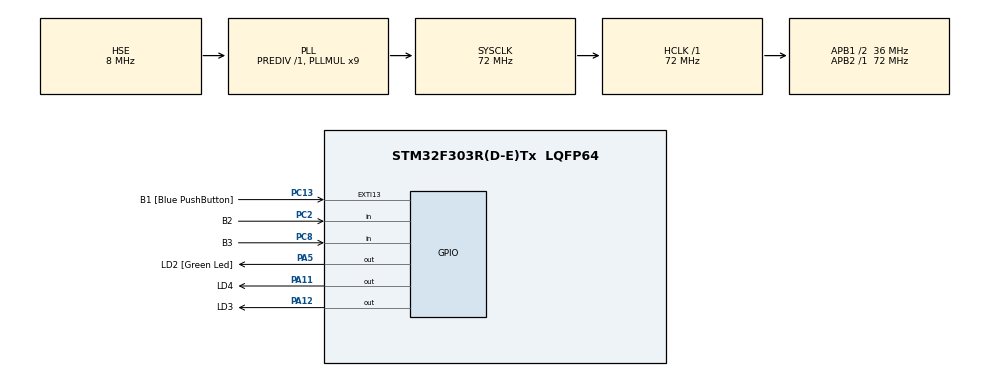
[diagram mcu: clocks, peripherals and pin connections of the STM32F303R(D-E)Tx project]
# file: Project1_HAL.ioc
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Mcu.Family=STM32F3
RCC.PLLSourceVirtual=RCC_PLLSOURCE_HSE
RCC.CortexFreq_Value=72000000
PC13.Signal=GPXTI13
PA14.GPIO_Label=TCK
RCC.SYSCLKSourceVirtual=RCC_SYSCLKSOURCE_PLLCLK
PC8.Signal=GPIO_Input
PC2.Signal=GPIO_Input
PA11.GPIO_Label=LD4
PC13.GPIO_Label=B1 [Blue PushButton]
RCC.APB1CLKDivider=RCC_HCLK_DIV2
PA12.GPIO_Label=LD3
ProjectManager.StackSize=0x400
PC8.GPIO_Label=B3
PA13.Signal=SYS_JTMS-SWDIO
PA12.GPIO_ModeDefaultOutputPP=GPIO_MODE_OUTPUT_OD
PA12.Signal=GPIO_Output
ProjectManager.TargetToolchain=STM32CubeIDE
RCC.HCLKFreq_Value=72000000
RCC.APB2TimFreq_Value=72000000
RCC.USBFreq_Value=72000000
RCC.LSE_VALUE=32768
RCC.AHBFreq_Value=72000000
PF0-OSC_IN.Mode=HSE-External-Oscillator
PA5.Signal=GPIO_Output
PA12.PinState=GPIO_PIN_SET
RCC.HSE_VALUE=8000000
board=NUCLEO-F303RE
RCC.RCC_PLLsource_Clock_Source_FROM_HSE=RCC_HSE_PREDIV_DIV2
RCC.PLLMUL=RCC_PLL_MUL9
PA11.GPIO_ModeDefaultOutputPP=GPIO_MODE_OUTPUT_PP
RCC.APB2Freq_Value=72000000
PA14.Mode=Serial_Wire
PA5.GPIO_PuPd=GPIO_NOPULL
PC2.GPIO_PuPd=GPIO_PULLUP
PA13.Mode=Serial_Wire
Mcu.Name=STM32F303R(D-E)Tx
PA13.GPIO_Label=TMS
PC8.GPIO_PuPd=GPIO_PULLDOWN
RCC.SYSCLKFreq_VALUE=72000000
Mcu.Package=LQFP64
PA5.GPIO_Label=LD2 [Green Led]
PC13.GPIO_ModeDefaultEXTI=GPIO_MODE_IT_FALLING
RCC.EnbaleCSS=true
PA11.Signal=GPIO_Output
PA14.Signal=SYS_JTCK-SWCLK
ProjectManager.HeapSize=0x200
RCC.HSI_VALUE=8000000
RCC.PLLP=RCC_PLLP_DIV4
PA5.GPIO_Speed=GPIO_SPEED_FREQ_LOW
RCC.PLLQ=7
NVIC.PriorityGroup=NVIC_PRIORITYGROUP_0
RCC.PLLM=8
RCC.PLLN=336
RCC.APB1TimFreq_Value=72000000
PF0-OSC_IN.Signal=RCC_OSC_IN
PF1-OSC_OUT.Mode=HSE-External-Oscillator
RCC.APB1Freq_Value=36000000
PA5.GPIO_Mode=GPIO_MODE_OUTPUT_PP
PC2.GPIO_Label=B2
PF1-OSC_OUT.Signal=RCC_OSC_OUT

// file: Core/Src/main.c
/* USER CODE BEGIN Header */
/**
  ******************************************************************************
  * @project-name	: Project 1 (with HAL Library)
  * @file           : main.c
  * @brief          : Main program body
  ******************************************************************************
  * @attention
  *
  * <h2><center>&copy; Copyright (c) 2021 STMicroelectronics.
  * All rights reserved.</center></h2>
  *
  * This software component is licensed by ST under BSD 3-Clause license,
  * the "License"; You may not use this file except in compliance with the
  * License. You may obtain a copy of the License at:
  *                        opensource.org/licenses/BSD-3-Clause
  *
  ******************************************************************************
  */
/* USER CODE END Header */
#include "main.h"

void SystemClock_Config(void);
static void MX_GPIO_Init(void);

int main(void)
{

  /* MCU Configuration--------------------------------------------------------*/

  /* Reset of all peripherals, Initializes the Flash interface and the Systick. */
  HAL_Init();

  /* Configure the system clock */
  SystemClock_Config();

  /* Initialize all configured peripherals */
  MX_GPIO_Init();

  /* Infinite loop */
  /* USER CODE BEGIN WHILE */
  while (1)
  {
	  //Check if the pull-up button is pressed.
	  if(!HAL_GPIO_ReadPin(B2_GPIO_Port, B2_Pin))
	  {

		  //50ms bounce time
		  HAL_Delay(50);

		  //Wait while the pull-up button is pressed.
		  while(!HAL_GPIO_ReadPin(B2_GPIO_Port, B2_Pin));

		  //50ms bounce time
		  HAL_Delay(50);

		  //Change the state of open-drain led
		  HAL_GPIO_TogglePin(LD3_GPIO_Port, LD3_Pin);

	  }

	  //Or check if the pull-down button is pressed.
	  else if (HAL_GPIO_ReadPin(B3_GPIO_Port, B3_Pin))
	  {

		  //50ms bounce time
		  HAL_Delay(50);

		  //Wait while the pull-down button is pressed.
		  while(HAL_GPIO_ReadPin(B3_GPIO_Port, B3_Pin));

		  //50ms bounce time
		  HAL_Delay(50);

		  //Change the state of push-pull led
		  HAL_GPIO_TogglePin(LD4_GPIO_Port, LD4_Pin);
	  }

	  else
	  {
		  continue;
	  }
    /* USER CODE END WHILE */
  }
}

void SystemClock_Config(void)
{
  RCC_OscInitTypeDef RCC_OscInitStruct = {0};
  RCC_ClkInitTypeDef RCC_ClkInitStruct = {0};

  /** Initializes the RCC Oscillators according to the specified parameters
  * in the RCC_OscInitTypeDef structure.
  */
  RCC_OscInitStruct.OscillatorType = RCC_OSCILLATORTYPE_HSE;
  RCC_OscInitStruct.HSEState = RCC_HSE_ON;
  RCC_OscInitStruct.HSIState = RCC_HSI_ON;
  RCC_OscInitStruct.PLL.PLLState = RCC_PLL_ON;
  RCC_OscInitStruct.PLL.PLLSource = RCC_PLLSOURCE_HSE;
  RCC_OscInitStruct.PLL.PLLMUL = RCC_PLL_MUL9;
  RCC_OscInitStruct.PLL.PREDIV = RCC_PREDIV_DIV1;
  if (HAL_RCC_OscConfig(&RCC_OscInitStruct) != HAL_OK)
  {
    Error_Handler();
  }
  /** Initializes the CPU, AHB and APB buses clocks
  */
  RCC_ClkInitStruct.ClockType = RCC_CLOCKTYPE_HCLK|RCC_CLOCKTYPE_SYSCLK
                              |RCC_CLOCKTYPE_PCLK1|RCC_CLOCKTYPE_PCLK2;
  RCC_ClkInitStruct.SYSCLKSource = RCC_SYSCLKSOURCE_PLLCLK;
  RCC_ClkInitStruct.AHBCLKDivider = RCC_SYSCLK_DIV1;
  RCC_ClkInitStruct.APB1CLKDivider = RCC_HCLK_DIV2;
  RCC_ClkInitStruct.APB2CLKDivider = RCC_HCLK_DIV1;

  if (HAL_RCC_ClockConfig(&RCC_ClkInitStruct, FLASH_LATENCY_2) != HAL_OK)
  {
    Error_Handler();
  }
  /** Enables the Clock Security System
  */
  HAL_RCC_EnableCSS();
}

static void MX_GPIO_Init(void)
{
  GPIO_InitTypeDef GPIO_InitStruct = {0};

  /* GPIO Ports Clock Enable */
  __HAL_RCC_GPIOC_CLK_ENABLE();
  __HAL_RCC_GPIOF_CLK_ENABLE();
  __HAL_RCC_GPIOA_CLK_ENABLE();

  /*Configure GPIO pin Output Level */
  HAL_GPIO_WritePin(GPIOA, LD2_Pin|LD4_Pin, GPIO_PIN_RESET);

  /*Configure GPIO pin Output Level */
  HAL_GPIO_WritePin(LD3_GPIO_Port, LD3_Pin, GPIO_PIN_SET);

  /*Configure GPIO pin : B1_Pin */
  GPIO_InitStruct.Pin = B1_Pin;
  GPIO_InitStruct.Mode = GPIO_MODE_IT_FALLING;
  GPIO_InitStruct.Pull = GPIO_NOPULL;
  HAL_GPIO_Init(B1_GPIO_Port, &GPIO_InitStruct);

  /*Configure GPIO pin : B2_Pin */
  GPIO_InitStruct.Pin = B2_Pin;
  GPIO_InitStruct.Mode = GPIO_MODE_INPUT;
  GPIO_InitStruct.Pull = GPIO_PULLUP;
  HAL_GPIO_Init(B2_GPIO_Port, &GPIO_InitStruct);

  /*Configure GPIO pins : LD2_Pin LD4_Pin */
  GPIO_InitStruct.Pin = LD2_Pin|LD4_Pin;
  GPIO_InitStruct.Mode = GPIO_MODE_OUTPUT_PP;
  GPIO_InitStruct.Pull = GPIO_NOPULL;
  GPIO_InitStruct.Speed = GPIO_SPEED_FREQ_LOW;
  HAL_GPIO_Init(GPIOA, &GPIO_InitStruct);

  /*Configure GPIO pin : B3_Pin */
  GPIO_InitStruct.Pin = B3_Pin;
  GPIO_InitStruct.Mode = GPIO_MODE_INPUT;
  GPIO_InitStruct.Pull = GPIO_PULLDOWN;
  HAL_GPIO_Init(B3_GPIO_Port, &GPIO_InitStruct);

  /*Configure GPIO pin : LD3_Pin */
  GPIO_InitStruct.Pin = LD3_Pin;
  GPIO_InitStruct.Mode = GPIO_MODE_OUTPUT_OD;
  GPIO_InitStruct.Pull = GPIO_NOPULL;
  GPIO_InitStruct.Speed = GPIO_SPEED_FREQ_LOW;
  HAL_GPIO_Init(LD3_GPIO_Port, &GPIO_InitStruct);

}

void Error_Handler(void)
{
  __disable_irq();
  while (1)
  {
  }
}

/************************ (C) COPYRIGHT STMicroelectronics *****END OF FILE****/
